AUTOSAR XML (schema 4.0)
package /primatec/light/lceComManager
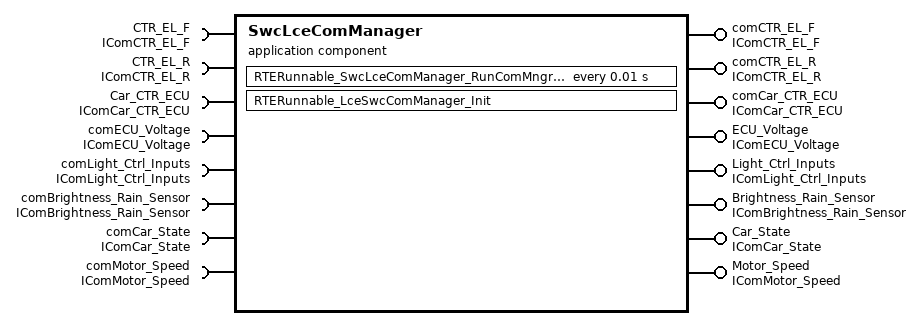
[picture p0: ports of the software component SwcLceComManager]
  application sw component type SwcLceComManager
    8 x provide port:
      comCTR_EL_F: provided-interface=IComCTR_EL_F
      comCTR_EL_R: provided-interface=IComCTR_EL_R
      comCar_CTR_ECU: provided-interface=IComCar_CTR_ECU
      ECU_Voltage: required-interface=IComECU_Voltage
      Light_Ctrl_Inputs: required-interface=IComLight_Ctrl_Inputs
      Brightness_Rain_Sensor: required-interface=IComBrightness_Rain_Sensor
      Car_State: required-interface=IComCar_State
      Motor_Speed: required-interface=IComMotor_Speed
    8 x require port:
      CTR_EL_F: provided-interface=IComCTR_EL_F
      CTR_EL_R: provided-interface=IComCTR_EL_R
      Car_CTR_ECU: provided-interface=IComCar_CTR_ECU
      comECU_Voltage: required-interface=IComECU_Voltage
      comLight_Ctrl_Inputs: required-interface=IComLight_Ctrl_Inputs
      comBrightness_Rain_Sensor: required-interface=IComBrightness_Rain_Sensor
      comCar_State: required-interface=IComCar_State
      comMotor_Speed: required-interface=IComMotor_Speed
    behavior SwcLceComManager_DefaultBehavior
      timing event periodRunnable_LceComManager10ms: start-on-event=RTERunnable_SwcLceComManager_RunComMngr_10msTask, period=0.01
      runnable RTERunnable_LceSwcComManager_Init: symbol=RTERunnable_SwcLceComManager_Init
      runnable RTERunnable_SwcLceComManager_RunComMngr_10msTask: can-be-invoked-concurrently=true
        data-receive-point-by-arguments:
          4 x access:
            DRPA_comLight_Ctrl_Inputs_ST_LP_LIN: accessed-variable=comLight_Ctrl_Inputs.ST_LP_LIN
            DRPA_comBrightness_Rain_Sensor_ST_RB_LIN: accessed-variable=comBrightness_Rain_Sensor.ST_RB_LIN
            DRPA_comCar_State_VEH_ST: accessed-variable=comCar_State.VEH_ST
            DRPA_comMotor_Speed_Motor_Speed: accessed-variable=comMotor_Speed.Motor_Speed
        data-send-points:
          6 x access:
            DRPA_comCTR_EL_F_CTR_FN_DR: accessed-variable=comCTR_EL_F.CTR_FN_DR
            DRPA_comCTR_EL_F_CTR_FN_POS: accessed-variable=comCTR_EL_F.CTR_FN_POS
            DRPA_comCTR_EL_F_CTR_FN_PAR: accessed-variable=comCTR_EL_F.CTR_FN_PAR
            DRPA_comCTR_EL_R_CTR_FN_DR: accessed-variable=comCTR_EL_R.CTR_FN_DR
            DRPA_comCTR_EL_R_CTR_FN_POS: accessed-variable=comCTR_EL_R.CTR_FN_POS
            DRPA_comCTR_EL_R_CTR_FN_PAR: accessed-variable=comCTR_EL_R.CTR_FN_PAR
